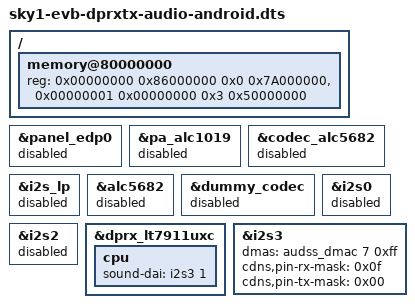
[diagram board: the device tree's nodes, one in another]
/*
 * Copyright (c) 2024, Cix Technology Group Co., Ltd. All rights reserved.
 *
 * SPDX-License-Identifier: BSD-3-Clause
 */

#include "sky1-evb.dts"
#include "sky1-android-common.dtsi"

&panel_edp0 {
	status = "disabled";
};

/ {
	memory@80000000 {
		#address-cells = <2>;
		#size-cells = <2>;
		device_type = "memory";
                reg = <0x00000000 0x86000000 0x0 0x7A000000>,
                      <0x00000001 0x00000000 0x3 0x50000000>;
	};
};

&pa_alc1019 {
	status = "disabled";
};

&codec_alc5682 {
	status = "disabled";
};

&i2s_lp {
	status = "disabled";
};

&alc5682 {
	status = "disabled";
};

&dummy_codec {
	status = "disabled";
};

&i2s0 {
	status = "disabled";
};

&i2s2 {
	status = "disabled";
};

&dprx_lt7911uxc {
	status = "okay";

	cpu {
		sound-dai = <&i2s3 1>;
	};
};

&i2s3 {
	dmas = <&audss_dmac 7 0xff>;
	dma-names = "rx";
	cdns,pin-rx-mask = /bits/ 8 <0x0f>;
	cdns,pin-tx-mask = /bits/ 8 <0x00>;
	status = "okay";
};
